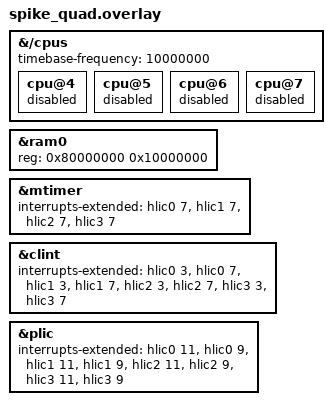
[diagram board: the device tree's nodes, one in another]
/* Spike -p4 -m256; shared 10 MHz CLINT. */
&{/cpus} {
  timebase-frequency = <10000000>;
  cpu@4 { status = "disabled"; };
  cpu@5 { status = "disabled"; };
  cpu@6 { status = "disabled"; };
  cpu@7 { status = "disabled"; };
};
&ram0 { reg = <0x80000000 0x10000000>; };
&mtimer { interrupts-extended = <&hlic0 7 &hlic1 7 &hlic2 7 &hlic3 7>; };
&clint {
  interrupts-extended = <&hlic0 3 &hlic0 7 &hlic1 3 &hlic1 7
                         &hlic2 3 &hlic2 7 &hlic3 3 &hlic3 7>;
};
&plic {
  interrupts-extended = <&hlic0 11 &hlic0 9 &hlic1 11 &hlic1 9
                         &hlic2 11 &hlic2 9 &hlic3 11 &hlic3 9>;
};
